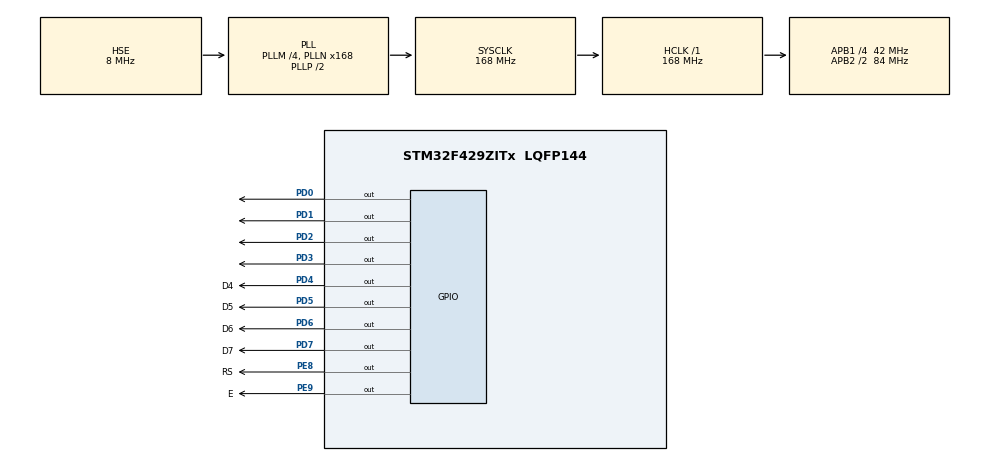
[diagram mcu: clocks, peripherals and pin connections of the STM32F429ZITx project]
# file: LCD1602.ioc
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Mcu.Family=STM32F4
Mcu.Name=STM32F429ZITx
Mcu.Package=LQFP144
NVIC.PriorityGroup=NVIC_PRIORITYGROUP_0
PD0.Signal=GPIO_Output
PD1.Signal=GPIO_Output
PD2.Signal=GPIO_Output
PD3.Signal=GPIO_Output
PD4.GPIO_Label=D4
PD4.Signal=GPIO_Output
PD5.GPIO_Label=D5
PD5.Signal=GPIO_Output
PD6.GPIO_Label=D6
PD6.Signal=GPIO_Output
PD7.GPIO_Label=D7
PD7.Signal=GPIO_Output
PE8.GPIO_Label=RS
PE8.Signal=GPIO_Output
PE9.GPIO_Label=E
PE9.Signal=GPIO_Output
PH0/OSC_IN.Mode=HSE-External-Clock-Source
PH0/OSC_IN.Signal=RCC_OSC_IN
PH1/OSC_OUT.Mode=HSE-External-Clock-Source
PH1/OSC_OUT.Signal=RCC_OSC_OUT
ProjectManager.HeapSize=0x200
ProjectManager.StackSize=0x400
ProjectManager.TargetToolchain=MDK-ARM V5.27
RCC.48MHZClocksFreq_Value=48000000
RCC.AHBFreq_Value=168000000
RCC.APB1CLKDivider=RCC_HCLK_DIV4
RCC.APB1Freq_Value=42000000
RCC.APB1TimFreq_Value=84000000
RCC.APB2CLKDivider=RCC_HCLK_DIV2
RCC.APB2Freq_Value=84000000
RCC.APB2TimFreq_Value=168000000
RCC.CortexFreq_Value=168000000
RCC.HCLKFreq_Value=168000000
RCC.HSE_VALUE=8000000
RCC.HSI_VALUE=16000000
RCC.LSE_VALUE=32768
RCC.PLLM=4
RCC.PLLN=168
RCC.PLLQ=7
RCC.PLLSourceVirtual=RCC_PLLSOURCE_HSE
RCC.SYSCLKFreq_VALUE=168000000
RCC.SYSCLKSource=RCC_SYSCLKSOURCE_PLLCLK
RCC.VCOOutputFreq_Value=336000000
board=STM32F429I-DISC1

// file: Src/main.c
/* USER CODE BEGIN Header */
/**
  ******************************************************************************
  * @file           : main.c
  * @brief          : Main program body
  ******************************************************************************
  * @attention
  *
  * <h2><center>&copy; Copyright (c) 2020 STMicroelectronics.
  * All rights reserved.</center></h2>
  *
  * This software component is licensed by ST under BSD 3-Clause license,
  * the "License"; You may not use this file except in compliance with the
  * License. You may obtain a copy of the License at:
  *                        opensource.org/licenses/BSD-3-Clause
  *
  ******************************************************************************
  */
/* USER CODE END Header */

#include "main.h"

/* USER CODE BEGIN Includes */
#include "lcd.h"
/* USER CODE END Includes */

void SystemClock_Config(void);
static void MX_GPIO_Init(void);

int main(void)
{

  /* MCU Configuration--------------------------------------------------------*/

  /* Reset of all peripherals, Initializes the Flash interface and the Systick. */
  HAL_Init();

  /* Configure the system clock */
  SystemClock_Config();

  /* Initialize all configured peripherals */
  MX_GPIO_Init();

  /* Infinite loop */
  /* USER CODE BEGIN WHILE */

	LCD_ini();

  while (1)
  {
    /* USER CODE END WHILE */

  }
}

void SystemClock_Config(void)
{
  RCC_OscInitTypeDef RCC_OscInitStruct = {0};
  RCC_ClkInitTypeDef RCC_ClkInitStruct = {0};

  /** Configure the main internal regulator output voltage
  */
  __HAL_RCC_PWR_CLK_ENABLE();
  __HAL_PWR_VOLTAGESCALING_CONFIG(PWR_REGULATOR_VOLTAGE_SCALE1);
  /** Initializes the CPU, AHB and APB busses clocks
  */
  RCC_OscInitStruct.OscillatorType = RCC_OSCILLATORTYPE_HSE;
  RCC_OscInitStruct.HSEState = RCC_HSE_BYPASS;
  RCC_OscInitStruct.PLL.PLLState = RCC_PLL_ON;
  RCC_OscInitStruct.PLL.PLLSource = RCC_PLLSOURCE_HSE;
  RCC_OscInitStruct.PLL.PLLM = 4;
  RCC_OscInitStruct.PLL.PLLN = 168;
  RCC_OscInitStruct.PLL.PLLP = RCC_PLLP_DIV2;
  RCC_OscInitStruct.PLL.PLLQ = 7;
  if (HAL_RCC_OscConfig(&RCC_OscInitStruct) != HAL_OK)
  {
    Error_Handler();
  }
  /** Initializes the CPU, AHB and APB busses clocks
  */
  RCC_ClkInitStruct.ClockType = RCC_CLOCKTYPE_HCLK|RCC_CLOCKTYPE_SYSCLK
                              |RCC_CLOCKTYPE_PCLK1|RCC_CLOCKTYPE_PCLK2;
  RCC_ClkInitStruct.SYSCLKSource = RCC_SYSCLKSOURCE_PLLCLK;
  RCC_ClkInitStruct.AHBCLKDivider = RCC_SYSCLK_DIV1;
  RCC_ClkInitStruct.APB1CLKDivider = RCC_HCLK_DIV4;
  RCC_ClkInitStruct.APB2CLKDivider = RCC_HCLK_DIV2;

  if (HAL_RCC_ClockConfig(&RCC_ClkInitStruct, FLASH_LATENCY_5) != HAL_OK)
  {
    Error_Handler();
  }
}

static void MX_GPIO_Init(void)
{
  GPIO_InitTypeDef GPIO_InitStruct = {0};

  /* GPIO Ports Clock Enable */
  __HAL_RCC_GPIOH_CLK_ENABLE();
  __HAL_RCC_GPIOE_CLK_ENABLE();
  __HAL_RCC_GPIOD_CLK_ENABLE();

  /*Configure GPIO pin Output Level */
  HAL_GPIO_WritePin(GPIOE, RS_Pin|E_Pin, GPIO_PIN_RESET);

  /*Configure GPIO pin Output Level */
  HAL_GPIO_WritePin(GPIOD, GPIO_PIN_0|GPIO_PIN_1|GPIO_PIN_2|GPIO_PIN_3
                          |D4_Pin|D5_Pin|D6_Pin|D7_Pin, GPIO_PIN_RESET);

  /*Configure GPIO pins : RS_Pin E_Pin */
  GPIO_InitStruct.Pin = RS_Pin|E_Pin;
  GPIO_InitStruct.Mode = GPIO_MODE_OUTPUT_PP;
  GPIO_InitStruct.Pull = GPIO_NOPULL;
  GPIO_InitStruct.Speed = GPIO_SPEED_FREQ_LOW;
  HAL_GPIO_Init(GPIOE, &GPIO_InitStruct);

  /*Configure GPIO pins : PD0 PD1 PD2 PD3
                           D4_Pin D5_Pin D6_Pin D7_Pin */
  GPIO_InitStruct.Pin = GPIO_PIN_0|GPIO_PIN_1|GPIO_PIN_2|GPIO_PIN_3
                          |D4_Pin|D5_Pin|D6_Pin|D7_Pin;
  GPIO_InitStruct.Mode = GPIO_MODE_OUTPUT_PP;
  GPIO_InitStruct.Pull = GPIO_NOPULL;
  GPIO_InitStruct.Speed = GPIO_SPEED_FREQ_LOW;
  HAL_GPIO_Init(GPIOD, &GPIO_InitStruct);

}

void Error_Handler(void)
{
}

/************************ (C) COPYRIGHT STMicroelectronics *****END OF FILE****/
